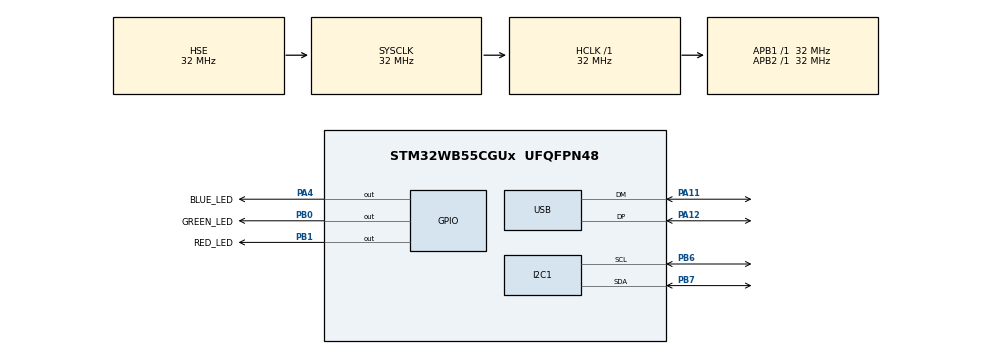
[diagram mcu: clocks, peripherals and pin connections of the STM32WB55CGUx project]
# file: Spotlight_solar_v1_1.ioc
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FREERTOS.Tasks01=defaultTask,24,1024,StartDefaultTask,Default,NULL,Dynamic,NULL,NULL
FREERTOS.configMINIMAL_STACK_SIZE=512
FREERTOS.configTOTAL_HEAP_SIZE=10000
FREERTOS.configUSE_TICKLESS_IDLE=2
I2C1.Timing=0x00707CBB
Mcu.Family=STM32WB
Mcu.Name=STM32WB55CGUx
Mcu.Package=UFQFPN48
NVIC.HSEM_IRQn=true\:5\:0\:false\:false\:true\:true\:false\:true
NVIC.I2C1_EV_IRQn=true\:5\:0\:false\:false\:true\:true\:true\:true
NVIC.PriorityGroup=NVIC_PRIORITYGROUP_4
NVIC.TIM1_UP_TIM16_IRQn=true\:0\:0\:false\:false\:true\:false\:false\:true
NVIC.TimeBase=TIM1_UP_TIM16_IRQn
NVIC.TimeBaseIP=TIM1
NVIC.USB_LP_IRQn=true\:5\:0\:false\:false\:true\:true\:false\:true
OSC_IN.Mode=HSE-External-Oscillator
OSC_IN.Signal=RCC_OSC_IN
OSC_OUT.Mode=HSE-External-Oscillator
OSC_OUT.Signal=RCC_OSC_OUT
PA11.Mode=Device
PA11.Signal=USB_DM
PA12.Mode=Device
PA12.Signal=USB_DP
PA13.Mode=Serial_Wire
PA13.Signal=SYS_JTMS-SWDIO
PA14.Mode=Serial_Wire
PA14.Signal=SYS_JTCK-SWCLK
PA4.GPIO_Label=BLUE_LED
PA4.Signal=GPIO_Output
PB0.GPIO_Label=GREEN_LED
PB0.Signal=GPIO_Output
PB1.GPIO_Label=RED_LED
PB1.Signal=GPIO_Output
PB6.Mode=I2C
PB6.Signal=I2C1_SCL
PB7.Mode=I2C
PB7.Signal=I2C1_SDA
PC14-OSC32_IN.Mode=LSE-External-Oscillator
PC14-OSC32_IN.Signal=RCC_OSC32_IN
PC15-OSC32_OUT.Mode=LSE-External-Oscillator
PC15-OSC32_OUT.Signal=RCC_OSC32_OUT
ProjectManager.HeapSize=0x200
ProjectManager.StackSize=0x400
ProjectManager.TargetToolchain=STM32CubeIDE
RCC.ADCFreq_Value=48000000
RCC.AHBFreq_Value=32000000
RCC.APB1Freq_Value=32000000
RCC.APB1TimFreq_Value=32000000
RCC.APB2Freq_Value=32000000
RCC.APB2TimFreq_Value=32000000
RCC.APB3Freq_Value=16000000
RCC.CortexFreq_Value=32000000
RCC.HCLKFreq_Value=32000000
RCC.HSE_VALUE=32000000
RCC.HSI48_VALUE=48000000
RCC.HSI_VALUE=16000000
RCC.PLLN=32
RCC.PLLSAI1N=24
RCC.RFWKPClockSelection=RCC_RFWKPCLKSOURCE_LSE
RCC.RTCClockSelection=RCC_RTCCLKSOURCE_LSE
RCC.SYSCLKFreq_VALUE=32000000
RCC.SYSCLKSource=RCC_SYSCLKSOURCE_HSE
RCC.USBFreq_Value=48000000
RCC.VCOOutputFreq_Value=128000000
RF1.Mode=RF1_Activate
RF1.Signal=RF_RF1
STM32_WPAN.APPLI_CONFIG_LOG_LEVEL=LOG_LEVEL_NONE
STM32_WPAN.CHANNEL=23
STM32_WPAN.PANID=1234
STM32_WPAN.THREAD_APPLICATION=FTD
USB_DEVICE.CLASS_NAME_FS=CDC
USB_DEVICE.VirtualMode=Cdc
USB_DEVICE.VirtualModeFS=Cdc_FS
VP_FREERTOS_VS_CMSIS_V2.Mode=CMSIS_V2
VP_HSEM_VS_HSEM.Mode=HSEM_Activate
VP_RTC_VS_RTC_Activate.Mode=RTC_Enabled
VP_STM32_WPAN_VS_THREAD.Mode=STM32_WPAN_Enabled
VP_SYS_VS_tim1.Mode=TIM1
VP_TINY_LPM_VS_TINY_LPM.Mode=TINY_LPM_Enabled
VP_USB_DEVICE_VS_USB_DEVICE_CDC_FS.Mode=CDC_FS
board=custom

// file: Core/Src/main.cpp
/* USER CODE BEGIN Header */
/**
  ******************************************************************************
  * @file           : main.c
  * @brief          : Main program body
  ******************************************************************************
  * @attention
  *
  * <h2><center>&copy; Copyright (c) 2020 STMicroelectronics.
  * All rights reserved.</center></h2>
  *
  * This software component is licensed by ST under Ultimate Liberty license
  * SLA0044, the "License"; You may not use this file except in compliance with
  * the License. You may obtain a copy of the License at:
  *                             www.st.com/SLA0044
  *
  ******************************************************************************
  */
/* USER CODE END Header */
#include "main.h"
#include "cmsis_os.h"
#include "i2c.h"
#include "rf.h"
#include "rtc.h"
#include "app_entry.h"
#include "app_common.h"
#include "usb_device.h"
#include "gpio.h"

/* USER CODE BEGIN Includes */
#include "myMain.h"

/* USER CODE END Includes */

void SystemClock_Config(void);
void MX_FREERTOS_Init(void);

int main(void)
{
  /* USER CODE BEGIN 1 */
//	  /**
//	   * The OPTVERR flag is wrongly set at power on
//	   * It shall be cleared before using any HAL_FLASH_xxx() api
//	   */
//	  __HAL_FLASH_CLEAR_FLAG(FLASH_FLAG_OPTVERR);
  /* USER CODE END 1 */

  /* MCU Configuration--------------------------------------------------------*/

  /* Reset of all peripherals, Initializes the Flash interface and the Systick. */
  HAL_Init();

  /* USER CODE BEGIN Init */
  Reset_Device();

  /* USER CODE END Init */

  /* Configure the system clock */
  SystemClock_Config();

  /* USER CODE BEGIN SysInit */
  Init_Exti( );

  /* USER CODE END SysInit */

  /* Initialize all configured peripherals */
  MX_GPIO_Init();
  MX_I2C1_Init();
  MX_RF_Init();
  MX_RTC_Init();
  MX_USB_Device_Init();

  /* Init scheduler */
  osKernelInitialize();  /* Call init function for freertos objects (in freertos.c) */
  MX_FREERTOS_Init();
  /* Start scheduler */
  osKernelStart();

  /* We should never get here as control is now taken by the scheduler */
  /* Infinite loop */
  while (1)
  {

  }
}

void SystemClock_Config(void)
{
  RCC_OscInitTypeDef RCC_OscInitStruct = {0};
  RCC_ClkInitTypeDef RCC_ClkInitStruct = {0};
  RCC_PeriphCLKInitTypeDef PeriphClkInitStruct = {0};

  /** Macro to configure the PLL multiplication factor
  */
  __HAL_RCC_PLL_PLLM_CONFIG(RCC_PLLM_DIV1);
  /** Macro to configure the PLL clock source
  */
  __HAL_RCC_PLL_PLLSOURCE_CONFIG(RCC_PLLSOURCE_MSI);
  /** Configure LSE Drive Capability
  */
  HAL_PWR_EnableBkUpAccess();
  __HAL_RCC_LSEDRIVE_CONFIG(RCC_LSEDRIVE_LOW);
  /** Configure the main internal regulator output voltage
  */
  __HAL_PWR_VOLTAGESCALING_CONFIG(PWR_REGULATOR_VOLTAGE_SCALE1);
  /** Initializes the RCC Oscillators according to the specified parameters
  * in the RCC_OscInitTypeDef structure.
  */
  RCC_OscInitStruct.OscillatorType = RCC_OSCILLATORTYPE_HSI|RCC_OSCILLATORTYPE_HSE
                              |RCC_OSCILLATORTYPE_LSE|RCC_OSCILLATORTYPE_MSI;
  RCC_OscInitStruct.HSEState = RCC_HSE_ON;
  RCC_OscInitStruct.LSEState = RCC_LSE_ON;
  RCC_OscInitStruct.HSIState = RCC_HSI_ON;
  RCC_OscInitStruct.MSIState = RCC_MSI_ON;
  RCC_OscInitStruct.HSICalibrationValue = RCC_HSICALIBRATION_DEFAULT;
  RCC_OscInitStruct.MSICalibrationValue = RCC_MSICALIBRATION_DEFAULT;
  RCC_OscInitStruct.MSIClockRange = RCC_MSIRANGE_6;
  RCC_OscInitStruct.PLL.PLLState = RCC_PLL_NONE;
  if (HAL_RCC_OscConfig(&RCC_OscInitStruct) != HAL_OK)
  {
    Error_Handler();
  }
  /** Configure the SYSCLKSource, HCLK, PCLK1 and PCLK2 clocks dividers
  */
  RCC_ClkInitStruct.ClockType = RCC_CLOCKTYPE_HCLK4|RCC_CLOCKTYPE_HCLK2
                              |RCC_CLOCKTYPE_HCLK|RCC_CLOCKTYPE_SYSCLK
                              |RCC_CLOCKTYPE_PCLK1|RCC_CLOCKTYPE_PCLK2;
  RCC_ClkInitStruct.SYSCLKSource = RCC_SYSCLKSOURCE_HSE;
  RCC_ClkInitStruct.AHBCLKDivider = RCC_SYSCLK_DIV1;
  RCC_ClkInitStruct.APB1CLKDivider = RCC_HCLK_DIV1;
  RCC_ClkInitStruct.APB2CLKDivider = RCC_HCLK_DIV1;
  RCC_ClkInitStruct.AHBCLK2Divider = RCC_SYSCLK_DIV1;
  RCC_ClkInitStruct.AHBCLK4Divider = RCC_SYSCLK_DIV1;

  if (HAL_RCC_ClockConfig(&RCC_ClkInitStruct, FLASH_LATENCY_1) != HAL_OK)
  {
    Error_Handler();
  }
  /** Initializes the peripherals clocks
  */
  PeriphClkInitStruct.PeriphClockSelection = RCC_PERIPHCLK_SMPS|RCC_PERIPHCLK_RFWAKEUP
                              |RCC_PERIPHCLK_RTC|RCC_PERIPHCLK_I2C1
                              |RCC_PERIPHCLK_USB;
  PeriphClkInitStruct.PLLSAI1.PLLN = 24;
  PeriphClkInitStruct.PLLSAI1.PLLP = RCC_PLLP_DIV2;
  PeriphClkInitStruct.PLLSAI1.PLLQ = RCC_PLLQ_DIV2;
  PeriphClkInitStruct.PLLSAI1.PLLR = RCC_PLLR_DIV2;
  PeriphClkInitStruct.PLLSAI1.PLLSAI1ClockOut = RCC_PLLSAI1_USBCLK;
  PeriphClkInitStruct.I2c1ClockSelection = RCC_I2C1CLKSOURCE_PCLK1;
  PeriphClkInitStruct.UsbClockSelection = RCC_USBCLKSOURCE_PLLSAI1;
  PeriphClkInitStruct.RTCClockSelection = RCC_RTCCLKSOURCE_LSE;
  PeriphClkInitStruct.RFWakeUpClockSelection = RCC_RFWKPCLKSOURCE_LSE;
  PeriphClkInitStruct.SmpsClockSelection = RCC_SMPSCLKSOURCE_HSI;
  PeriphClkInitStruct.SmpsDivSelection = RCC_SMPSCLKDIV_RANGE1;
  if (HAL_RCCEx_PeriphCLKConfig(&PeriphClkInitStruct) != HAL_OK)
  {
    Error_Handler();
  }
  /** Enable MSI Auto calibration
  */
  HAL_RCCEx_EnableMSIPLLMode();
}

 /**
  * @brief  Period elapsed callback in non blocking mode
  * @note   This function is called  when TIM1 interrupt took place, inside
  * HAL_TIM_IRQHandler(). It makes a direct call to HAL_IncTick() to increment
  * a global variable "uwTick" used as application time base.
  * @param  htim : TIM handle
  * @retval None
  */
void HAL_TIM_PeriodElapsedCallback(TIM_HandleTypeDef *htim)
{
  if (htim->Instance == TIM1) {
    HAL_IncTick();
  }
}

void Error_Handler(void)
{
  __disable_irq();
  while (1)
  {
  }
}

/************************ (C) COPYRIGHT STMicroelectronics *****END OF FILE****/
